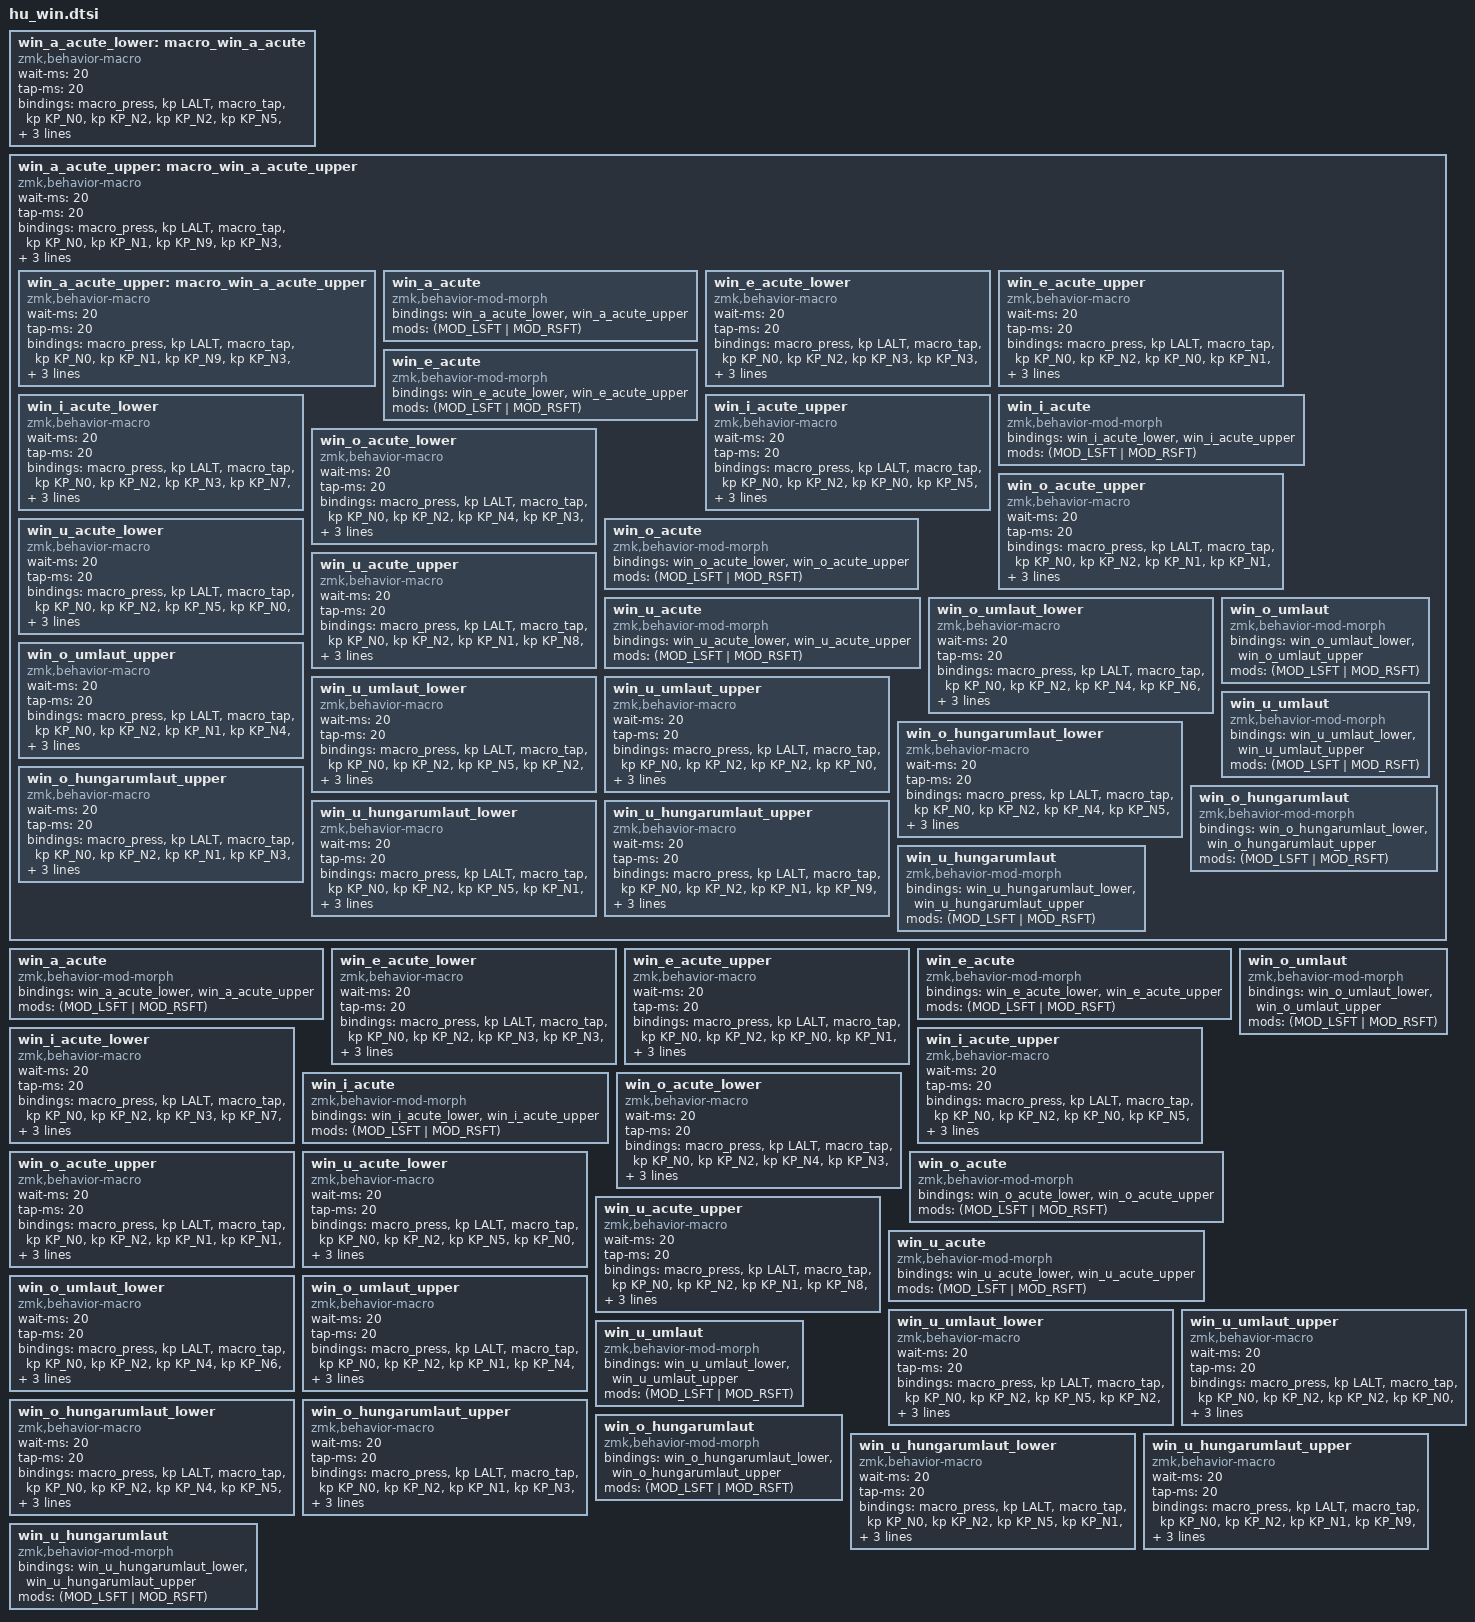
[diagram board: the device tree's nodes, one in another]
// á — Windows Alt+0225
win_a_acute_lower: macro_win_a_acute {
	compatible = "zmk,behavior-macro",
	#binding-cells = <0>;
	wait-ms = <20>;
	tap-ms = <20>;
	bindings =
		<&macro_press &kp LALT>,
		<&macro_tap &kp KP_N0 &kp KP_N2 &kp KP_N2 &kp KP_N5>,
		<&macro_release &kp LALT>;
	label = "WIN_A_ACUTE_LOWER";
	display-name = "WIN_A_ACUTE_LOWER";
};

// Á — Windows Alt+0193
  win_a_acute_upper: macro_win_a_acute_upper {
      compatible = "zmk,behavior-macro";
      #binding-cells = <0>;
      wait-ms = <20>;
      tap-ms = <20>;
      bindings =
          <&macro_press &kp LALT>,
          <&macro_tap &kp KP_N0 &kp KP_N1 &kp KP_N9 &kp KP_N3>,
          <&macro_release &kp LALT>;
      label = "WIN_A_ACUTE_UPPER";
      display-name = "WIN_A_ACUTE_UPPER";
  };

  win_a_acute: win_a_acute {
    compatible = "zmk,behavior-mod-morph";
    #binding-cells = <0>;
    bindings = <&win_a_acute_lower>, <&win_a_acute_upper>;
    mods = <(MOD_LSFT | MOD_RSFT)>;
  };

  // é — Windows Alt+0233
  win_e_acute_lower: win_e_acute_lower {
    compatible = "zmk,behavior-macro";
    #binding-cells = <0>;
    wait-ms = <20>;
    tap-ms = <20>;
    bindings =
        <&macro_press &kp LALT>,
        <&macro_tap &kp KP_N0 &kp KP_N2 &kp KP_N3 &kp KP_N3>,
        <&macro_release &kp LALT>;
    label = "WIN_E_ACUTE_LOWER";
    display-name = "WIN_E_ACUTE_LOWER";
  };

  // É — Windows Alt+0201
  win_e_acute_upper: win_e_acute_upper {
    compatible = "zmk,behavior-macro";
    #binding-cells = <0>;
    wait-ms = <20>;
    tap-ms = <20>;
    bindings =
        <&macro_press &kp LALT>,
        <&macro_tap &kp KP_N0 &kp KP_N2 &kp KP_N0 &kp KP_N1>,
        <&macro_release &kp LALT>;
    label = "WIN_E_ACUTE_UPPER";
    display-name = "WIN_E_ACUTE_UPPER";
  };

  win_e_acute: win_e_acute {
    compatible = "zmk,behavior-mod-morph";
    #binding-cells = <0>;
    bindings = <&win_e_acute_lower>, <&win_e_acute_upper>;
    mods = <(MOD_LSFT | MOD_RSFT)>;
  };

  // í — Windows Alt+0237
  win_i_acute_lower: win_i_acute_lower {
    compatible = "zmk,behavior-macro";
    #binding-cells = <0>;
    wait-ms = <20>;
    tap-ms = <20>;
    bindings =
        <&macro_press &kp LALT>,
        <&macro_tap &kp KP_N0 &kp KP_N2 &kp KP_N3 &kp KP_N7>,
        <&macro_release &kp LALT>;
    label = "WIN_I_ACUTE_LOWER";
    display-name = "WIN_I_ACUTE_LOWER";
  };

  // Í — Windows Alt+0205
  win_i_acute_upper: win_i_acute_upper {
    compatible = "zmk,behavior-macro";
    #binding-cells = <0>;
    wait-ms = <20>;
    tap-ms = <20>;
    bindings =
        <&macro_press &kp LALT>,
        <&macro_tap &kp KP_N0 &kp KP_N2 &kp KP_N0 &kp KP_N5>,
        <&macro_release &kp LALT>;
    label = "WIN_I_ACUTE_UPPER";
    display-name = "WIN_I_ACUTE_UPPER";
  };

  win_i_acute: win_i_acute {
    compatible = "zmk,behavior-mod-morph";
    #binding-cells = <0>;
    bindings = <&win_i_acute_lower>, <&win_i_acute_upper>;
    mods = <(MOD_LSFT | MOD_RSFT)>;
  };

  // ó — Windows Alt+0243
  win_o_acute_lower: win_o_acute_lower {
    compatible = "zmk,behavior-macro";
    #binding-cells = <0>;
    wait-ms = <20>;
    tap-ms = <20>;
    bindings =
        <&macro_press &kp LALT>,
        <&macro_tap &kp KP_N0 &kp KP_N2 &kp KP_N4 &kp KP_N3>,
        <&macro_release &kp LALT>;
    label = "WIN_O_ACUTE_LOWER";
    display-name = "WIN_O_ACUTE_LOWER";
  };

  // Ó — Windows Alt+0211
  win_o_acute_upper: win_o_acute_upper {
    compatible = "zmk,behavior-macro";
    #binding-cells = <0>;
    wait-ms = <20>;
    tap-ms = <20>;
    bindings =
        <&macro_press &kp LALT>,
        <&macro_tap &kp KP_N0 &kp KP_N2 &kp KP_N1 &kp KP_N1>,
        <&macro_release &kp LALT>;
    label = "WIN_O_ACUTE_UPPER";
    display-name = "WIN_O_ACUTE_UPPER";
  };

  win_o_acute: win_o_acute {
    compatible = "zmk,behavior-mod-morph";
    #binding-cells = <0>;
    bindings = <&win_o_acute_lower>, <&win_o_acute_upper>;
    mods = <(MOD_LSFT | MOD_RSFT)>;
  };

  // ú — Windows Alt+0250
  win_u_acute_lower: win_u_acute_lower {
    compatible = "zmk,behavior-macro";
    #binding-cells = <0>;
    wait-ms = <20>;
    tap-ms = <20>;
    bindings =
        <&macro_press &kp LALT>,
        <&macro_tap &kp KP_N0 &kp KP_N2 &kp KP_N5 &kp KP_N0>,
        <&macro_release &kp LALT>;
    label = "WIN_U_ACUTE_LOWER";
    display-name = "WIN_U_ACUTE_LOWER";
  };

  // Ú — Windows Alt+0218
  win_u_acute_upper: win_u_acute_upper {
    compatible = "zmk,behavior-macro";
    #binding-cells = <0>;
    wait-ms = <20>;
    tap-ms = <20>;
    bindings =
        <&macro_press &kp LALT>,
        <&macro_tap &kp KP_N0 &kp KP_N2 &kp KP_N1 &kp KP_N8>,
        <&macro_release &kp LALT>;
    label = "WIN_U_ACUTE_UPPER";
    display-name = "WIN_U_ACUTE_UPPER";
  };

  win_u_acute: win_u_acute {
    compatible = "zmk,behavior-mod-morph";
    #binding-cells = <0>;
    bindings = <&win_u_acute_lower>, <&win_u_acute_upper>;
    mods = <(MOD_LSFT | MOD_RSFT)>;
  };

  // ö — Windows Alt+0246
  win_o_umlaut_lower: win_o_umlaut_lower {
    compatible = "zmk,behavior-macro";
    #binding-cells = <0>;
    wait-ms = <20>;
    tap-ms = <20>;
    bindings =
        <&macro_press &kp LALT>,
        <&macro_tap &kp KP_N0 &kp KP_N2 &kp KP_N4 &kp KP_N6>,
        <&macro_release &kp LALT>;
    label = "WIN_O_UMLAUT_LOWER";
    display-name = "WIN_O_UMLAUT_LOWER";
  };

  // Ö — Windows Alt+0214
  win_o_umlaut_upper: win_o_umlaut_upper {
    compatible = "zmk,behavior-macro";
    #binding-cells = <0>;
    wait-ms = <20>;
    tap-ms = <20>;
    bindings =
        <&macro_press &kp LALT>,
        <&macro_tap &kp KP_N0 &kp KP_N2 &kp KP_N1 &kp KP_N4>,
        <&macro_release &kp LALT>;
    label = "WIN_O_UMLAUT_UPPER";
    display-name = "WIN_O_UMLAUT_UPPER";
  };

  win_o_umlaut: win_o_umlaut {
    compatible = "zmk,behavior-mod-morph";
    #binding-cells = <0>;
    bindings = <&win_o_umlaut_lower>, <&win_o_umlaut_upper>;
    mods = <(MOD_LSFT | MOD_RSFT)>;
  };

  // ü — Windows Alt+0252
  win_u_umlaut_lower: win_u_umlaut_lower {
    compatible = "zmk,behavior-macro";
    #binding-cells = <0>;
    wait-ms = <20>;
    tap-ms = <20>;
    bindings =
        <&macro_press &kp LALT>,
        <&macro_tap &kp KP_N0 &kp KP_N2 &kp KP_N5 &kp KP_N2>,
        <&macro_release &kp LALT>;
    label = "WIN_U_UMLAUT_LOWER";
    display-name = "WIN_U_UMLAUT_LOWER";
  };

  // Ü — Windows Alt+0220
  win_u_umlaut_upper: win_u_umlaut_upper {
    compatible = "zmk,behavior-macro";
    #binding-cells = <0>;
    wait-ms = <20>;
    tap-ms = <20>;
    bindings =
        <&macro_press &kp LALT>,
        <&macro_tap &kp KP_N0 &kp KP_N2 &kp KP_N2 &kp KP_N0>,
        <&macro_release &kp LALT>;
    label = "WIN_U_UMLAUT_UPPER";
    display-name = "WIN_U_UMLAUT_UPPER";
  };

  win_u_umlaut: win_u_umlaut {
    compatible = "zmk,behavior-mod-morph";
    #binding-cells = <0>;
    bindings = <&win_u_umlaut_lower>, <&win_u_umlaut_upper>;
    mods = <(MOD_LSFT | MOD_RSFT)>;
  };

  // ő — Windows Alt+0245 (Windows-1250)
  win_o_hungarumlaut_lower: win_o_hungarumlaut_lower {
    compatible = "zmk,behavior-macro";
    #binding-cells = <0>;
    wait-ms = <20>;
    tap-ms = <20>;
    bindings =
        <&macro_press &kp LALT>,
        <&macro_tap &kp KP_N0 &kp KP_N2 &kp KP_N4 &kp KP_N5>,
        <&macro_release &kp LALT>;
    label = "WIN_O_HUNGARUMLAUT_LOWER";
    display-name = "WIN_O_HUNGARUMLAUT_LOWER";
  };

  // Ő — Windows Alt+0213 (Windows-1250)
  win_o_hungarumlaut_upper: win_o_hungarumlaut_upper {
    compatible = "zmk,behavior-macro";
    #binding-cells = <0>;
    wait-ms = <20>;
    tap-ms = <20>;
    bindings =
        <&macro_press &kp LALT>,
        <&macro_tap &kp KP_N0 &kp KP_N2 &kp KP_N1 &kp KP_N3>,
        <&macro_release &kp LALT>;
    label = "WIN_O_HUNGARUMLAUT_UPPER";
    display-name = "WIN_O_HUNGARUMLAUT_UPPER";
  };

  win_o_hungarumlaut: win_o_hungarumlaut {
    compatible = "zmk,behavior-mod-morph";
    #binding-cells = <0>;
    bindings = <&win_o_hungarumlaut_lower>, <&win_o_hungarumlaut_upper>;
    mods = <(MOD_LSFT | MOD_RSFT)>;
  };

  // ű — Windows Alt+0251 (Windows-1250)
  win_u_hungarumlaut_lower: win_u_hungarumlaut_lower {
    compatible = "zmk,behavior-macro";
    #binding-cells = <0>;
    wait-ms = <20>;
    tap-ms = <20>;
    bindings =
        <&macro_press &kp LALT>,
        <&macro_tap &kp KP_N0 &kp KP_N2 &kp KP_N5 &kp KP_N1>,
        <&macro_release &kp LALT>;
    label = "WIN_U_HUNGARUMLAUT_LOWER";
    display-name = "WIN_U_HUNGARUMLAUT_LOWER";
  };

  // Ű — Windows Alt+0219 (Windows-1250)
  win_u_hungarumlaut_upper: win_u_hungarumlaut_upper {
    compatible = "zmk,behavior-macro";
    #binding-cells = <0>;
    wait-ms = <20>;
    tap-ms = <20>;
    bindings =
        <&macro_press &kp LALT>,
        <&macro_tap &kp KP_N0 &kp KP_N2 &kp KP_N1 &kp KP_N9>,
        <&macro_release &kp LALT>;
    label = "WIN_U_HUNGARUMLAUT_UPPER";
    display-name = "WIN_U_HUNGARUMLAUT_UPPER";
  };

  win_u_hungarumlaut: win_u_hungarumlaut {
    compatible = "zmk,behavior-mod-morph";
    #binding-cells = <0>;
    bindings = <&win_u_hungarumlaut_lower>, <&win_u_hungarumlaut_upper>;
    mods = <(MOD_LSFT | MOD_RSFT)>;
  };

// Á — Windows Alt+0193
  win_a_acute_upper: macro_win_a_acute_upper {
// Á — Windows Alt+0193
  win_a_acute_upper: macro_win_a_acute_upper {
      compatible = "zmk,behavior-macro";
      #binding-cells = <0>;
      wait-ms = <20>;
      tap-ms = <20>;
      bindings =
          <&macro_press &kp LALT>,
          <&macro_tap &kp KP_N0 &kp KP_N1 &kp KP_N9 &kp KP_N3>,
          <&macro_release &kp LALT>;
      label = "WIN_A_ACUTE_UPPER";
      display-name = "WIN_A_ACUTE_UPPER";
  };

  win_a_acute: win_a_acute {
    compatible = "zmk,behavior-mod-morph";
    #binding-cells = <0>;
    bindings = <&win_a_acute_lower>, <&win_a_acute_upper>;
    mods = <(MOD_LSFT | MOD_RSFT)>;
  };

  // é — Windows Alt+0233
  win_e_acute_lower: win_e_acute_lower {
    compatible = "zmk,behavior-macro";
    #binding-cells = <0>;
    wait-ms = <20>;
    tap-ms = <20>;
    bindings =
        <&macro_press &kp LALT>,
        <&macro_tap &kp KP_N0 &kp KP_N2 &kp KP_N3 &kp KP_N3>,
        <&macro_release &kp LALT>;
    label = "WIN_E_ACUTE_LOWER";
    display-name = "WIN_E_ACUTE_LOWER";
  };

  // É — Windows Alt+0201
  win_e_acute_upper: win_e_acute_upper {
    compatible = "zmk,behavior-macro";
    #binding-cells = <0>;
    wait-ms = <20>;
    tap-ms = <20>;
    bindings =
        <&macro_press &kp LALT>,
        <&macro_tap &kp KP_N0 &kp KP_N2 &kp KP_N0 &kp KP_N1>,
        <&macro_release &kp LALT>;
    label = "WIN_E_ACUTE_UPPER";
    display-name = "WIN_E_ACUTE_UPPER";
  };

  win_e_acute: win_e_acute {
    compatible = "zmk,behavior-mod-morph";
    #binding-cells = <0>;
    bindings = <&win_e_acute_lower>, <&win_e_acute_upper>;
    mods = <(MOD_LSFT | MOD_RSFT)>;
  };

  // í — Windows Alt+0237
  win_i_acute_lower: win_i_acute_lower {
    compatible = "zmk,behavior-macro";
    #binding-cells = <0>;
    wait-ms = <20>;
    tap-ms = <20>;
    bindings =
        <&macro_press &kp LALT>,
        <&macro_tap &kp KP_N0 &kp KP_N2 &kp KP_N3 &kp KP_N7>,
        <&macro_release &kp LALT>;
    label = "WIN_I_ACUTE_LOWER";
    display-name = "WIN_I_ACUTE_LOWER";
  };

  // Í — Windows Alt+0205
  win_i_acute_upper: win_i_acute_upper {
    compatible = "zmk,behavior-macro";
    #binding-cells = <0>;
    wait-ms = <20>;
    tap-ms = <20>;
    bindings =
        <&macro_press &kp LALT>,
        <&macro_tap &kp KP_N0 &kp KP_N2 &kp KP_N0 &kp KP_N5>,
        <&macro_release &kp LALT>;
    label = "WIN_I_ACUTE_UPPER";
    display-name = "WIN_I_ACUTE_UPPER";
  };

  win_i_acute: win_i_acute {
    compatible = "zmk,behavior-mod-morph";
    #binding-cells = <0>;
    bindings = <&win_i_acute_lower>, <&win_i_acute_upper>;
    mods = <(MOD_LSFT | MOD_RSFT)>;
  };

  // ó — Windows Alt+0243
  win_o_acute_lower: win_o_acute_lower {
    compatible = "zmk,behavior-macro";
    #binding-cells = <0>;
    wait-ms = <20>;
    tap-ms = <20>;
    bindings =
        <&macro_press &kp LALT>,
        <&macro_tap &kp KP_N0 &kp KP_N2 &kp KP_N4 &kp KP_N3>,
        <&macro_release &kp LALT>;
    label = "WIN_O_ACUTE_LOWER";
    display-name = "WIN_O_ACUTE_LOWER";
  };

  // Ó — Windows Alt+0211
  win_o_acute_upper: win_o_acute_upper {
    compatible = "zmk,behavior-macro";
    #binding-cells = <0>;
    wait-ms = <20>;
    tap-ms = <20>;
    bindings =
        <&macro_press &kp LALT>,
        <&macro_tap &kp KP_N0 &kp KP_N2 &kp KP_N1 &kp KP_N1>,
        <&macro_release &kp LALT>;
    label = "WIN_O_ACUTE_UPPER";
    display-name = "WIN_O_ACUTE_UPPER";
  };

  win_o_acute: win_o_acute {
    compatible = "zmk,behavior-mod-morph";
    #binding-cells = <0>;
    bindings = <&win_o_acute_lower>, <&win_o_acute_upper>;
    mods = <(MOD_LSFT | MOD_RSFT)>;
  };

  // ú — Windows Alt+0250
  win_u_acute_lower: win_u_acute_lower {
    compatible = "zmk,behavior-macro";
    #binding-cells = <0>;
    wait-ms = <20>;
    tap-ms = <20>;
    bindings =
        <&macro_press &kp LALT>,
        <&macro_tap &kp KP_N0 &kp KP_N2 &kp KP_N5 &kp KP_N0>,
        <&macro_release &kp LALT>;
    label = "WIN_U_ACUTE_LOWER";
    display-name = "WIN_U_ACUTE_LOWER";
  };

  // Ú — Windows Alt+0218
  win_u_acute_upper: win_u_acute_upper {
    compatible = "zmk,behavior-macro";
    #binding-cells = <0>;
    wait-ms = <20>;
    tap-ms = <20>;
    bindings =
        <&macro_press &kp LALT>,
        <&macro_tap &kp KP_N0 &kp KP_N2 &kp KP_N1 &kp KP_N8>,
        <&macro_release &kp LALT>;
    label = "WIN_U_ACUTE_UPPER";
    display-name = "WIN_U_ACUTE_UPPER";
  };

  win_u_acute: win_u_acute {
    compatible = "zmk,behavior-mod-morph";
    #binding-cells = <0>;
    bindings = <&win_u_acute_lower>, <&win_u_acute_upper>;
    mods = <(MOD_LSFT | MOD_RSFT)>;
  };

  // ö — Windows Alt+0246
  win_o_umlaut_lower: win_o_umlaut_lower {
    compatible = "zmk,behavior-macro";
    #binding-cells = <0>;
    wait-ms = <20>;
    tap-ms = <20>;
    bindings =
        <&macro_press &kp LALT>,
        <&macro_tap &kp KP_N0 &kp KP_N2 &kp KP_N4 &kp KP_N6>,
        <&macro_release &kp LALT>;
    label = "WIN_O_UMLAUT_LOWER";
    display-name = "WIN_O_UMLAUT_LOWER";
  };

  // Ö — Windows Alt+0214
  win_o_umlaut_upper: win_o_umlaut_upper {
    compatible = "zmk,behavior-macro";
    #binding-cells = <0>;
    wait-ms = <20>;
    tap-ms = <20>;
    bindings =
        <&macro_press &kp LALT>,
        <&macro_tap &kp KP_N0 &kp KP_N2 &kp KP_N1 &kp KP_N4>,
        <&macro_release &kp LALT>;
    label = "WIN_O_UMLAUT_UPPER";
    display-name = "WIN_O_UMLAUT_UPPER";
  };

  win_o_umlaut: win_o_umlaut {
    compatible = "zmk,behavior-mod-morph";
    #binding-cells = <0>;
    bindings = <&win_o_umlaut_lower>, <&win_o_umlaut_upper>;
    mods = <(MOD_LSFT | MOD_RSFT)>;
  };

  // ü — Windows Alt+0252
  win_u_umlaut_lower: win_u_umlaut_lower {
    compatible = "zmk,behavior-macro";
    #binding-cells = <0>;
    wait-ms = <20>;
    tap-ms = <20>;
    bindings =
        <&macro_press &kp LALT>,
        <&macro_tap &kp KP_N0 &kp KP_N2 &kp KP_N5 &kp KP_N2>,
        <&macro_release &kp LALT>;
    label = "WIN_U_UMLAUT_LOWER";
    display-name = "WIN_U_UMLAUT_LOWER";
  };

  // Ü — Windows Alt+0220
  win_u_umlaut_upper: win_u_umlaut_upper {
    compatible = "zmk,behavior-macro";
    #binding-cells = <0>;
    wait-ms = <20>;
    tap-ms = <20>;
    bindings =
        <&macro_press &kp LALT>,
        <&macro_tap &kp KP_N0 &kp KP_N2 &kp KP_N2 &kp KP_N0>,
        <&macro_release &kp LALT>;
    label = "WIN_U_UMLAUT_UPPER";
    display-name = "WIN_U_UMLAUT_UPPER";
  };

  win_u_umlaut: win_u_umlaut {
    compatible = "zmk,behavior-mod-morph";
    #binding-cells = <0>;
    bindings = <&win_u_umlaut_lower>, <&win_u_umlaut_upper>;
    mods = <(MOD_LSFT | MOD_RSFT)>;
  };

  // ő — Windows Alt+0245 (Windows-1250)
  win_o_hungarumlaut_lower: win_o_hungarumlaut_lower {
    compatible = "zmk,behavior-macro";
    #binding-cells = <0>;
    wait-ms = <20>;
    tap-ms = <20>;
    bindings =
        <&macro_press &kp LALT>,
        <&macro_tap &kp KP_N0 &kp KP_N2 &kp KP_N4 &kp KP_N5>,
        <&macro_release &kp LALT>;
    label = "WIN_O_HUNGARUMLAUT_LOWER";
    display-name = "WIN_O_HUNGARUMLAUT_LOWER";
  };

  // Ő — Windows Alt+0213 (Windows-1250)
  win_o_hungarumlaut_upper: win_o_hungarumlaut_upper {
    compatible = "zmk,behavior-macro";
    #binding-cells = <0>;
    wait-ms = <20>;
    tap-ms = <20>;
    bindings =
        <&macro_press &kp LALT>,
        <&macro_tap &kp KP_N0 &kp KP_N2 &kp KP_N1 &kp KP_N3>,
        <&macro_release &kp LALT>;
    label = "WIN_O_HUNGARUMLAUT_UPPER";
    display-name = "WIN_O_HUNGARUMLAUT_UPPER";
  };

  win_o_hungarumlaut: win_o_hungarumlaut {
    compatible = "zmk,behavior-mod-morph";
    #binding-cells = <0>;
    bindings = <&win_o_hungarumlaut_lower>, <&win_o_hungarumlaut_upper>;
    mods = <(MOD_LSFT | MOD_RSFT)>;
  };

  // ű — Windows Alt+0251 (Windows-1250)
  win_u_hungarumlaut_lower: win_u_hungarumlaut_lower {
    compatible = "zmk,behavior-macro";
    #binding-cells = <0>;
    wait-ms = <20>;
    tap-ms = <20>;
    bindings =
        <&macro_press &kp LALT>,
        <&macro_tap &kp KP_N0 &kp KP_N2 &kp KP_N5 &kp KP_N1>,
        <&macro_release &kp LALT>;
    label = "WIN_U_HUNGARUMLAUT_LOWER";
    display-name = "WIN_U_HUNGARUMLAUT_LOWER";
  };

  // Ű — Windows Alt+0219 (Windows-1250)
  win_u_hungarumlaut_upper: win_u_hungarumlaut_upper {
    compatible = "zmk,behavior-macro";
    #binding-cells = <0>;
    wait-ms = <20>;
    tap-ms = <20>;
    bindings =
        <&macro_press &kp LALT>,
        <&macro_tap &kp KP_N0 &kp KP_N2 &kp KP_N1 &kp KP_N9>,
        <&macro_release &kp LALT>;
    label = "WIN_U_HUNGARUMLAUT_UPPER";
    display-name = "WIN_U_HUNGARUMLAUT_UPPER";
  };

  win_u_hungarumlaut: win_u_hungarumlaut {
    compatible = "zmk,behavior-mod-morph";
    #binding-cells = <0>;
    bindings = <&win_u_hungarumlaut_lower>, <&win_u_hungarumlaut_upper>;
    mods = <(MOD_LSFT | MOD_RSFT)>;
  };
      compatible = "zmk,behavior-macro";
      #binding-cells = <0>;
      wait-ms = <20>;
      tap-ms = <20>;
      bindings =
          <&macro_press &kp LALT>,
          <&macro_tap &kp KP_N0 &kp KP_N1 &kp KP_N9 &kp KP_N3>,
          <&macro_release &kp LALT>;
      label = "WIN_A_ACUTE_UPPER";
      display-name = "WIN_A_ACUTE_UPPER";
  };

  win_a_acute: win_a_acute {
    compatible = "zmk,behavior-mod-morph";
    #binding-cells = <0>;
    bindings = <&win_a_acute_lower>, <&win_a_acute_upper>;
    mods = <(MOD_LSFT | MOD_RSFT)>;
  };

  // é — Windows Alt+0233
  win_e_acute_lower: win_e_acute_lower {
    compatible = "zmk,behavior-macro";
    #binding-cells = <0>;
    wait-ms = <20>;
    tap-ms = <20>;
    bindings =
        <&macro_press &kp LALT>,
        <&macro_tap &kp KP_N0 &kp KP_N2 &kp KP_N3 &kp KP_N3>,
        <&macro_release &kp LALT>;
    label = "WIN_E_ACUTE_LOWER";
    display-name = "WIN_E_ACUTE_LOWER";
  };

  // É — Windows Alt+0201
  win_e_acute_upper: win_e_acute_upper {
    compatible = "zmk,behavior-macro";
    #binding-cells = <0>;
    wait-ms = <20>;
    tap-ms = <20>;
    bindings =
        <&macro_press &kp LALT>,
        <&macro_tap &kp KP_N0 &kp KP_N2 &kp KP_N0 &kp KP_N1>,
        <&macro_release &kp LALT>;
    label = "WIN_E_ACUTE_UPPER";
    display-name = "WIN_E_ACUTE_UPPER";
  };

  win_e_acute: win_e_acute {
    compatible = "zmk,behavior-mod-morph";
    #binding-cells = <0>;
    bindings = <&win_e_acute_lower>, <&win_e_acute_upper>;
    mods = <(MOD_LSFT | MOD_RSFT)>;
  };

  // í — Windows Alt+0237
  win_i_acute_lower: win_i_acute_lower {
    compatible = "zmk,behavior-macro";
    #binding-cells = <0>;
    wait-ms = <20>;
    tap-ms = <20>;
    bindings =
        <&macro_press &kp LALT>,
        <&macro_tap &kp KP_N0 &kp KP_N2 &kp KP_N3 &kp KP_N7>,
        <&macro_release &kp LALT>;
    label = "WIN_I_ACUTE_LOWER";
    display-name = "WIN_I_ACUTE_LOWER";
  };

  // Í — Windows Alt+0205
  win_i_acute_upper: win_i_acute_upper {
    compatible = "zmk,behavior-macro";
    #binding-cells = <0>;
    wait-ms = <20>;
    tap-ms = <20>;
    bindings =
        <&macro_press &kp LALT>,
        <&macro_tap &kp KP_N0 &kp KP_N2 &kp KP_N0 &kp KP_N5>,
        <&macro_release &kp LALT>;
    label = "WIN_I_ACUTE_UPPER";
    display-name = "WIN_I_ACUTE_UPPER";
  };

  win_i_acute: win_i_acute {
    compatible = "zmk,behavior-mod-morph";
    #binding-cells = <0>;
    bindings = <&win_i_acute_lower>, <&win_i_acute_upper>;
    mods = <(MOD_LSFT | MOD_RSFT)>;
  };

  // ó — Windows Alt+0243
  win_o_acute_lower: win_o_acute_lower {
    compatible = "zmk,behavior-macro";
    #binding-cells = <0>;
    wait-ms = <20>;
    tap-ms = <20>;
    bindings =
        <&macro_press &kp LALT>,
        <&macro_tap &kp KP_N0 &kp KP_N2 &kp KP_N4 &kp KP_N3>,
        <&macro_release &kp LALT>;
    label = "WIN_O_ACUTE_LOWER";
    display-name = "WIN_O_ACUTE_LOWER";
  };

  // Ó — Windows Alt+0211
  win_o_acute_upper: win_o_acute_upper {
    compatible = "zmk,behavior-macro";
    #binding-cells = <0>;
    wait-ms = <20>;
    tap-ms = <20>;
    bindings =
        <&macro_press &kp LALT>,
        <&macro_tap &kp KP_N0 &kp KP_N2 &kp KP_N1 &kp KP_N1>,
        <&macro_release &kp LALT>;
    label = "WIN_O_ACUTE_UPPER";
    display-name = "WIN_O_ACUTE_UPPER";
  };

  win_o_acute: win_o_acute {
    compatible = "zmk,behavior-mod-morph";
    #binding-cells = <0>;
    bindings = <&win_o_acute_lower>, <&win_o_acute_upper>;
    mods = <(MOD_LSFT | MOD_RSFT)>;
  };

  // ú — Windows Alt+0250
  win_u_acute_lower: win_u_acute_lower {
    compatible = "zmk,behavior-macro";
    #binding-cells = <0>;
    wait-ms = <20>;
    tap-ms = <20>;
    bindings =
        <&macro_press &kp LALT>,
        <&macro_tap &kp KP_N0 &kp KP_N2 &kp KP_N5 &kp KP_N0>,
        <&macro_release &kp LALT>;
    label = "WIN_U_ACUTE_LOWER";
    display-name = "WIN_U_ACUTE_LOWER";
  };

  // Ú — Windows Alt+0218
  win_u_acute_upper: win_u_acute_upper {
    compatible = "zmk,behavior-macro";
    #binding-cells = <0>;
    wait-ms = <20>;
    tap-ms = <20>;
    bindings =
        <&macro_press &kp LALT>,
        <&macro_tap &kp KP_N0 &kp KP_N2 &kp KP_N1 &kp KP_N8>,
        <&macro_release &kp LALT>;
    label = "WIN_U_ACUTE_UPPER";
    display-name = "WIN_U_ACUTE_UPPER";
  };

  win_u_acute: win_u_acute {
    compatible = "zmk,behavior-mod-morph";
    #binding-cells = <0>;
    bindings = <&win_u_acute_lower>, <&win_u_acute_upper>;
    mods = <(MOD_LSFT | MOD_RSFT)>;
  };

  // ö — Windows Alt+0246
  win_o_umlaut_lower: win_o_umlaut_lower {
    compatible = "zmk,behavior-macro";
    #binding-cells = <0>;
    wait-ms = <20>;
    tap-ms = <20>;
    bindings =
        <&macro_press &kp LALT>,
        <&macro_tap &kp KP_N0 &kp KP_N2 &kp KP_N4 &kp KP_N6>,
        <&macro_release &kp LALT>;
    label = "WIN_O_UMLAUT_LOWER";
    display-name = "WIN_O_UMLAUT_LOWER";
  };

  // Ö — Windows Alt+0214
  win_o_umlaut_upper: win_o_umlaut_upper {
    compatible = "zmk,behavior-macro";
    #binding-cells = <0>;
    wait-ms = <20>;
    tap-ms = <20>;
    bindings =
        <&macro_press &kp LALT>,
        <&macro_tap &kp KP_N0 &kp KP_N2 &kp KP_N1 &kp KP_N4>,
        <&macro_release &kp LALT>;
    label = "WIN_O_UMLAUT_UPPER";
    display-name = "WIN_O_UMLAUT_UPPER";
  };

  win_o_umlaut: win_o_umlaut {
    compatible = "zmk,behavior-mod-morph";
    #binding-cells = <0>;
    bindings = <&win_o_umlaut_lower>, <&win_o_umlaut_upper>;
    mods = <(MOD_LSFT | MOD_RSFT)>;
  };

  // ü — Windows Alt+0252
  win_u_umlaut_lower: win_u_umlaut_lower {
    compatible = "zmk,behavior-macro";
    #binding-cells = <0>;
    wait-ms = <20>;
    tap-ms = <20>;
    bindings =
        <&macro_press &kp LALT>,
        <&macro_tap &kp KP_N0 &kp KP_N2 &kp KP_N5 &kp KP_N2>,
        <&macro_release &kp LALT>;
    label = "WIN_U_UMLAUT_LOWER";
    display-name = "WIN_U_UMLAUT_LOWER";
  };

  // Ü — Windows Alt+0220
  win_u_umlaut_upper: win_u_umlaut_upper {
    compatible = "zmk,behavior-macro";
    #binding-cells = <0>;
    wait-ms = <20>;
    tap-ms = <20>;
    bindings =
        <&macro_press &kp LALT>,
        <&macro_tap &kp KP_N0 &kp KP_N2 &kp KP_N2 &kp KP_N0>,
        <&macro_release &kp LALT>;
    label = "WIN_U_UMLAUT_UPPER";
    display-name = "WIN_U_UMLAUT_UPPER";
  };

  win_u_umlaut: win_u_umlaut {
    compatible = "zmk,behavior-mod-morph";
    #binding-cells = <0>;
    bindings = <&win_u_umlaut_lower>, <&win_u_umlaut_upper>;
    mods = <(MOD_LSFT | MOD_RSFT)>;
  };

  // ő — Windows Alt+0245 (Windows-1250)
  win_o_hungarumlaut_lower: win_o_hungarumlaut_lower {
    compatible = "zmk,behavior-macro";
    #binding-cells = <0>;
    wait-ms = <20>;
    tap-ms = <20>;
    bindings =
        <&macro_press &kp LALT>,
        <&macro_tap &kp KP_N0 &kp KP_N2 &kp KP_N4 &kp KP_N5>,
        <&macro_release &kp LALT>;
    label = "WIN_O_HUNGARUMLAUT_LOWER";
    display-name = "WIN_O_HUNGARUMLAUT_LOWER";
  };

  // Ő — Windows Alt+0213 (Windows-1250)
  win_o_hungarumlaut_upper: win_o_hungarumlaut_upper {
    compatible = "zmk,behavior-macro";
    #binding-cells = <0>;
    wait-ms = <20>;
    tap-ms = <20>;
    bindings =
        <&macro_press &kp LALT>,
        <&macro_tap &kp KP_N0 &kp KP_N2 &kp KP_N1 &kp KP_N3>,
        <&macro_release &kp LALT>;
    label = "WIN_O_HUNGARUMLAUT_UPPER";
    display-name = "WIN_O_HUNGARUMLAUT_UPPER";
  };

  win_o_hungarumlaut: win_o_hungarumlaut {
    compatible = "zmk,behavior-mod-morph";
    #binding-cells = <0>;
    bindings = <&win_o_hungarumlaut_lower>, <&win_o_hungarumlaut_upper>;
    mods = <(MOD_LSFT | MOD_RSFT)>;
  };

  // ű — Windows Alt+0251 (Windows-1250)
  win_u_hungarumlaut_lower: win_u_hungarumlaut_lower {
    compatible = "zmk,behavior-macro";
    #binding-cells = <0>;
    wait-ms = <20>;
    tap-ms = <20>;
    bindings =
        <&macro_press &kp LALT>,
        <&macro_tap &kp KP_N0 &kp KP_N2 &kp KP_N5 &kp KP_N1>,
        <&macro_release &kp LALT>;
    label = "WIN_U_HUNGARUMLAUT_LOWER";
    display-name = "WIN_U_HUNGARUMLAUT_LOWER";
  };

  // Ű — Windows Alt+0219 (Windows-1250)
  win_u_hungarumlaut_upper: win_u_hungarumlaut_upper {
    compatible = "zmk,behavior-macro";
    #binding-cells = <0>;
    wait-ms = <20>;
    tap-ms = <20>;
    bindings =
        <&macro_press &kp LALT>,
        <&macro_tap &kp KP_N0 &kp KP_N2 &kp KP_N1 &kp KP_N9>,
        <&macro_release &kp LALT>;
    label = "WIN_U_HUNGARUMLAUT_UPPER";
    display-name = "WIN_U_HUNGARUMLAUT_UPPER";
  };

  win_u_hungarumlaut: win_u_hungarumlaut {
    compatible = "zmk,behavior-mod-morph";
    #binding-cells = <0>;
    bindings = <&win_u_hungarumlaut_lower>, <&win_u_hungarumlaut_upper>;
    mods = <(MOD_LSFT | MOD_RSFT)>;
  };
